AUTOSAR XML (schema 4-2-2)
package /AUTOLIV/SoftwareComponents/EIM
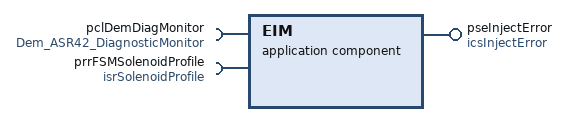
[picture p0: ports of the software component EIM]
  application sw component type EIM: category=SWC  # EIM_AC_ErrorInjectionFault
    require port pclDemDiagMonitor: required-com-specs=[SetEventStatus, ResetEventStatus, ResetEventDebounceStatus, PrestoreFreezeFrame, ClearPrestoredFreezeFrame], required-interface=Dem_ASR42_DiagnosticMonitor
    require port prrFSMSolenoidProfile: nonqueued-receiver-com-spec{data-element=au8SelectedProfile, init-value=6 x KU8_PROFILE_UNLOCK}, required-interface=isrSolenoidProfile  # # Architecture Element ID ARCH_SW_EIM_prrFSMSolenoidProfile # Description - The runnable shall read the solenoid profile for each solenoid # Data Flow ## Inputs ## Outputs - {Solenoid Profile for Solenoid 1, 2, 3, 4, 5, 6} #Linked Runnable - EIM_ManageAecStatus # Traceability
    provide port pseInjectError: server-com-spec{operation=EIM_ManageAecStatus, queue-length=1}, provided-interface=icsInjectError  # # Architecture Element ID ARCH_SW_EIM_pseInjectError # Description - The EIM_ManageAecStatus shall be called cyclic in order to manage error injection # Data Flow ## Inputs: - None ## Outputs: - None # Linked Runnable - EIM_ManageAecStatus # Traceability
